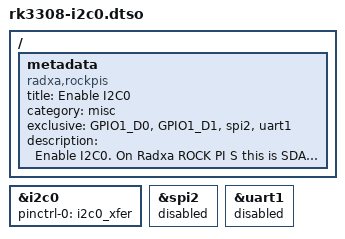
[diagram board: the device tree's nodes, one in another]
/dts-v1/;
/plugin/;

/ {
	metadata {
		title = "Enable I2C0";
		compatible = "radxa,rockpis", "radxa,rock-s0";
		category = "misc";
		exclusive = "GPIO1_D0", "GPIO1_D1", "spi2", "uart1";
		description = "Enable I2C0.
On Radxa ROCK PI S this is SDA pin 23 & SCL pin 24.
On ROCK S0 this is SDA pin 23 & SCL pin 24.";
    };
};

&i2c0 {
	status = "okay";
	pinctrl-names = "default";
	pinctrl-0 = <&i2c0_xfer>;
};

&spi2 {
	status = "disabled";
};

&uart1 {
	status = "disabled";
};
